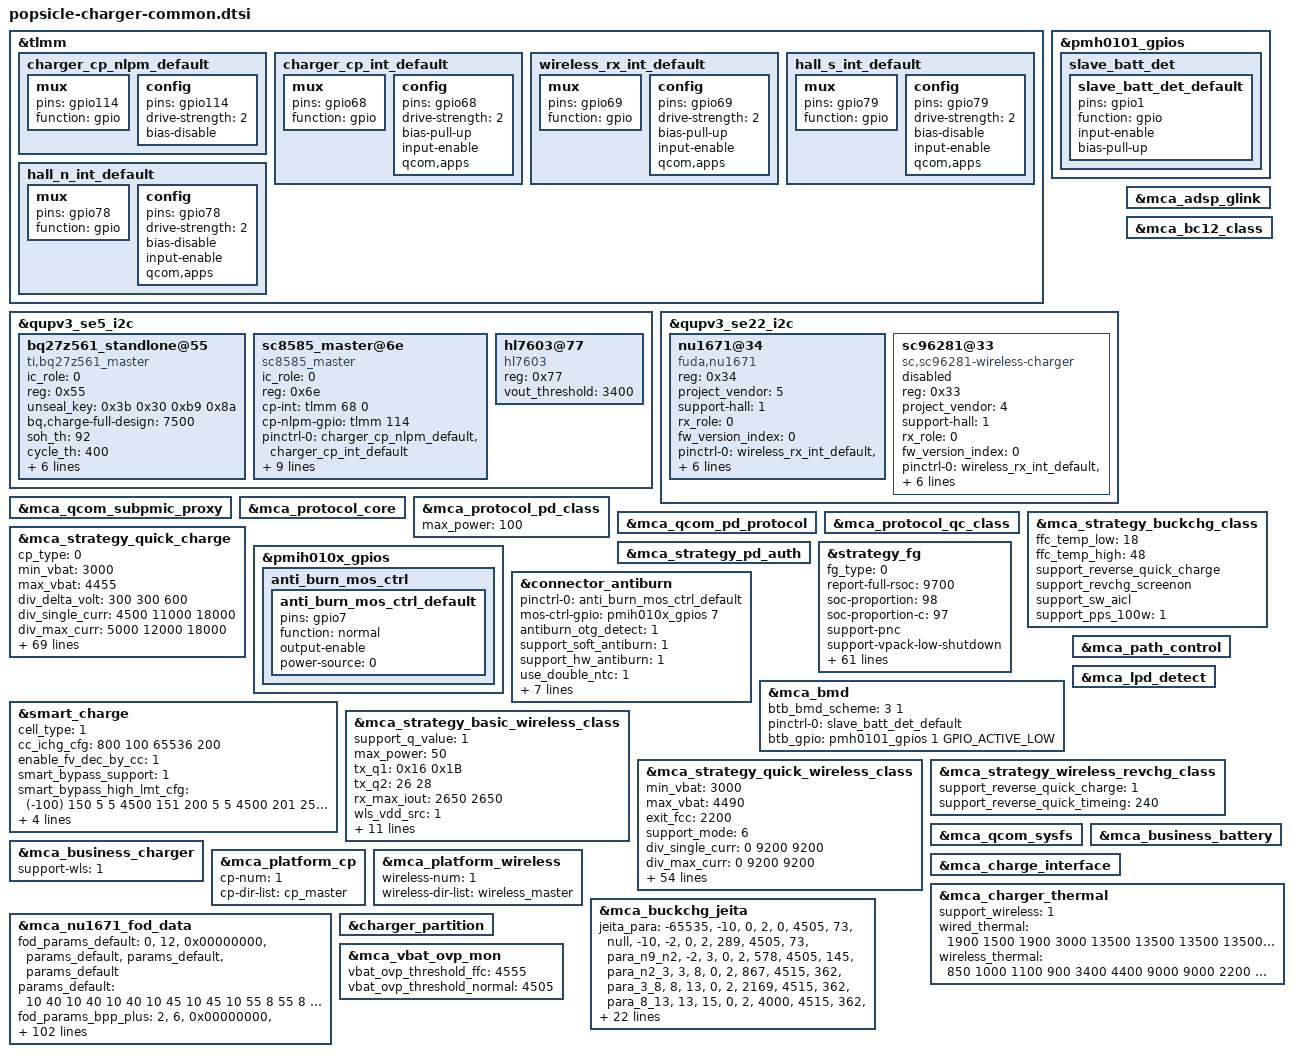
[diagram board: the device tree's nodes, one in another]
#include "mca.dtsi"

&tlmm {
	charger_cp_nlpm_default: charger_cp_nlpm_default {
		mux {
			pins = "gpio114";
			function = "gpio";
		};
		config {
			pins = "gpio114";
			drive-strength = <2>;   /* 2 mA */
			bias-disable;
		};
	};

	charger_cp_int_default: charger_cp_int_default {
		mux {
			pins = "gpio68";
			function = "gpio";
		};
		config {
			pins = "gpio68";
			drive-strength = <2>;   /* 2 mA */
			bias-pull-up;
			input-enable;
			qcom,apps;
		};
	};

	wireless_rx_int_default: wireless_rx_int_default {
		mux {
			pins = "gpio69";
			function = "gpio";
		};

		config {
			pins = "gpio69";
			drive-strength = <2>;
			bias-pull-up;
			input-enable;
			qcom,apps;
		};
	};

	hall_s_int_default: hall_s_int_default {
		mux {
			pins = "gpio79";
			function = "gpio";
		};

		config {
			pins = "gpio79";
			drive-strength = <2>;
			bias-disable;
			input-enable;
			qcom,apps;
		};
	};

	hall_n_int_default: hall_n_int_default {
		mux {
			pins = "gpio78";
			function = "gpio";
		};

		config {
			pins = "gpio78";
			drive-strength = <2>;
			bias-disable;
			input-enable;
			qcom,apps;
		};
	};

};

&pmh0101_gpios {
	slave_batt_det {
		slave_batt_det_default: slave_batt_det_default {
			pins = "gpio1";
			function = "gpio";
			input-enable;
			bias-pull-up;
		};
	};
};


&qupv3_se5_i2c {
	status = "ok";
	#address-cells = <1>;
	#size-cells = <0>;
	bq27z561_standlone@55 {
		compatible = "ti,bq27z561_master";
		ic_role = <0>;
		reg = <0x55>;
		unseal_key = /bits/ 8 <0x3b 0x30 0xb9 0x8a>;
		bq,charge-full-design = <7500>;
		soh_th = <92>;
		cycle_th = <400>;
		cycle_step = <50>;
		resistance-id = <100000>;
		support_batt_manager_4p0;
		base_termv = <2850>;
		delta_soh_compesation = <
			0 0
			50 0
			100 2
			150 4
			200 6
			250 8
			300 10
			350 12
			400 14
			450 16
			500 18
			550 19>;
		status = "ok";
	};

	sc8585_master@6e {
		compatible = "sc8585_master";
		status = "ok";
		ic_role = <0>;
		reg = <0x6e>;
		cp-int= <&tlmm 68 0>;
		cp-nlpm-gpio = <&tlmm 114 0x00>;
		pinctrl-names = "default";
		pinctrl-0 = <&charger_cp_nlpm_default>, <&charger_cp_int_default>;
		bat-ovp-threshold = <4775>;
		bat-ovp-alarm-threshold = <4650>;
		bus-ovp-threshold = <21000 12000 6000>;
		usb-ovp-threshold = <21000 14000 7500>;
		bus-ocp-threshold = <5000 5500 5000>;
		wpc-ovp-threshold = <21000>;
		out-ovp-threshold = <5000>;
		pmid2-uvp-threshold = <350 350 100>;
		pmid2-ovp-threshold = <600>;
	};

	hl7603@77 {
		compatible = "hl7603";
		reg = <0x77>;
		vout_threshold = <3400>;
	};
};

&qupv3_se22_i2c {
	status = "ok";
	#address-cells = <1>;
	#size-cells = <0>;

	nu1671@34 {
		compatible = "fuda,nu1671";
		reg = <0x34>;
		project_vendor = <5>;
		support-hall = <1>;
		rx_role = <0>;
		fw_version_index = <0>;
		pinctrl-names = "default";
		pinctrl-0 = <&wireless_rx_int_default>, <&hall_s_int_default>, <&hall_n_int_default>;
		rx-int = <&tlmm 69 0x00>;
		pwr-det-int = <&tlmm 57 0x00>;
		sleep-rx-gpio = <&tlmm 200 0x00>;
		hall-s-int = <&tlmm 79 0x00>;
		hall-n-int = <&tlmm 78 0x00>;
	};

	sc96281@33 {
		status = "disabled";
		compatible = "sc,sc96281-wireless-charger";
		reg = <0x33>;
		project_vendor = <4>;
		support-hall = <1>;
		rx_role = <0>;
		fw_version_index = <0>;
		pinctrl-names = "default";
		pinctrl-0 = <&wireless_rx_int_default>, <&hall_s_int_default>, <&hall_n_int_default>;
		rx-int = <&tlmm 69 0x00>;
		pwr-det-int = <&tlmm 57 0x00>;
		sleep-rx-gpio = <&tlmm 200 0x00>;
		hall-s-int = <&tlmm 79 0x00>;
		hall-n-int = <&tlmm 78 0x00>;
	};
};

&mca_adsp_glink {
	status = "ok";
};

&mca_bc12_class {
	status = "ok";
};

&mca_qcom_subpmic_proxy {
	status = "ok";
};

&mca_protocol_core {
	status = "ok";
};

&mca_protocol_pd_class {
	status = "ok";
	max_power = <100>;
};

&mca_qcom_pd_protocol {
	status = "ok";
};

&mca_protocol_qc_class {
	status = "ok";
};

&mca_strategy_buckchg_class {
	status = "ok";
	ffc_temp_low = <18>;
	ffc_temp_high = <48>;
	support_reverse_quick_charge;
	support_revchg_screenon;
	support_sw_aicl;
	support_pps_100w = <1>;
};

&mca_strategy_quick_charge {
	status = "ok";
	cp_type = <0>;
	min_vbat = <3000>;
	max_vbat = <4455>;
	div_delta_volt = <300 300 600>;
	div_single_curr = <4500 11000 18000>;
	div_max_curr = <5000 12000 18000>;
	non_mi_pps_max_curr = <4500 11000 18000>;
	support_mode = <6>;
	support_cp_vfc = <1>;
	real_curr_max = <17500>;
	curr_monitor_current = <17600>;
	curr_monitor_time_s = <120>;
	support_cancel_compensation;
	max_vbat_threshold = <4500>;
	en_buck_parallel_chg = <1>;
	buck_icl_fcc_curr = <1000 3000>;
	buck_en_th = <13000 2500>;
	buck_dis_th = <13000 3850>;

	/* volt_ratio, cur_gap, vbat_gap, vstep_ratio */
	vstep_para =
		"1", "300", "2000", "0", "2",
		"2", "300", "2000", "0", "4",
		"4", "300", "8400", "20", "20",
		"4", "300", "4400", "20", "10",
		"4", "300", "1400", "10", "5",
		"4", "300", "900", "10", "2",
		"1", "800", "2000", "0", "2",
		"2", "800", "2000", "0", "4",
		"4", "800", "8000", "0", "10",
		"4", "800", "6000", "0", "5",
		"4", "800", "4000", "0", "2";

	batt_para =
		"0", "atl", "batt_para_atl";
	/* temp_low, temp_high, low_hys, high_hys, max_curr, normal_para, ffc_para, normal_stage, ffc_stage */
	batt_para_atl =
		"-65535", "13", "0", "2", "0", "null", "null", "null", "null",
		"13", "15", "0", "1", "4338", "normal_para_13_15", "null", "null", "null",
		"15", "18", "0", "1", "7953", "normal_para_15_18", "null", "null", "null",
		"18", "23", "0", "1", "10845", "normal_para_18_23", "ffc_para_18_23", "null", "ffc_stage_18_23",
		"23", "25", "0", "1", "18000", "normal_para_23_25", "ffc_para_23_25", "null", "ffc_stage_23_25",
		"25", "35", "0", "0", "18000", "normal_para_25_35", "ffc_para_25_35", "null", "ffc_stage_25_35",
		"35", "43", "1", "0", "18000", "normal_para_35_43", "ffc_para_35_43", "null", "ffc_stage_35_43",
		"43", "48", "1", "0", "18000", "normal_para_43_48", "ffc_para_43_48", "null", "ffc_stage_43_48",
		"48", "65535", "2", "0", "0", "null", "null", "null", "null";

	/* volt, curr_max, curr_min */
	normal_para_13_15 =
		"3895", "4338", "2892",
		"4510", "2892", "800";

	normal_para_15_18 =
		"3995", "7953", "5784",
		"4145", "5784", "2892",
		"4510", "2892", "800";

	normal_para_18_23 =
		"3895", "10845", "7953",
		"3995", "7953", "5784",
		"4145", "5784", "2892",
		"4490", "2892", "800";
	ffc_para_18_23 =
		"3895", "10845", "7953",
		"3995", "7953", "5784",
		"4145", "5784", "2892",
		"4540", "2892", "940";
	ffc_stage_18_23 = <0 1 0 0 0 0 0 0>;

	normal_para_23_25 =
		"4015", "18000", "8676",
		"4395", "8676", "5784",
		"4490", "5784", "800";
	ffc_para_23_25 =
		"4015", "18000", "12400",
		"4105", "12400", "10845",
		"4295", "10845", "8676",
		"4395", "8676", "5784",
		"4540", "5784", "1736";
	ffc_stage_23_25 = <0 0 0 0 0 0 0 0 0 0>;

	normal_para_25_35 =
		"4015", "18000", "8676",
		"4490", "8676", "800";
	ffc_para_25_35 =
		"4015", "18000", "12400",
		"4105", "12400", "10845",
		"4495", "10845", "8676",
		"4540", "8676", "1736";
	ffc_stage_25_35 = <0 0 0 0 0 0 0 0>;

	normal_para_35_43 =
		"4015", "18000", "8676",
		"4470", "8676", "800";
	ffc_para_35_43 =
		"4015", "18000", "12400",
		"4105", "12400", "10845",
		"4495", "10845", "8676",
		"4540", "8676", "3109";
	ffc_stage_35_43 = <0 0 0 0 0 0 0 0>;

	normal_para_43_48 =
		"4015", "18000", "8676",
		"4470", "8676", "800";
	ffc_para_43_48 =
		"4015", "18000", "12400",
		"4105", "12400", "10845",
		"4495", "10845", "8676",
		"4540", "8676", "5712";
	ffc_stage_43_48 = <0 0 0 0 0 0 0 0>;
};

&mca_strategy_pd_auth {
	status = "ok";
};

&strategy_fg {
	status = "ok";
	fg_type = <0>;
	report-full-rsoc = <9700>;
	soc-proportion = <98>;
	soc-proportion-c = <97>;
	support-pnc;

	support-vpack-low-shutdown;
	vcutoff_shutdown_delay = <3030>;
	vcutoff_sw = <2930>;
	vcutoff_fw = <3030>;

	support-cc-vcutoff;
	/* temp_low, temp_high, low_temp_hys, high_temp_hys, vterm_para_name */
	cc_vcutoff_cfg =
		"-65535", "-6", "0", "2", "cc_para0",
		"-6", "0", "2", "2", "cc_para1",
		"0", "10", "2", "2", "cc_para2",
		"10", "60", "2", "0", "cc_para3",
		"60", "65535", "2", "0", "cc_para4";
	/* cycle_count, vterm_fw, vterm_shutdown_delay, vempty */
	cc_para0 =
		"400", "2650", "2600", "2500",
		"800", "2700", "2650", "2550",
		"1200", "2850", "2800", "2700",
		"65535", "2950", "2900", "2800";
	cc_para1 =
		"400", "2700", "2650", "2550",
		"800", "2850", "2800", "2700",
		"1200", "2950", "2900", "2800",
		"65535", "3050", "3000", "2900";
	cc_para2 =
		"400", "2850", "2850", "2750",
		"800", "2950", "2950", "2850",
		"1200", "3000", "3000", "2900",
		"65535", "3100", "3100", "3000";
	cc_para3 =
		"400", "3030", "3030", "2930",
		"800", "3130", "3130", "3030",
		"1200", "3200", "3200", "3100",
		"65535", "3260", "3260", "3160";
	cc_para4 =
		"65535", "3260", "3260", "3160";

	support-dod-vcutoff-v2;
	weight = <20 18 15>;
	/* temp_low, temp_high, low_temp_hys, high_temp_hys, vterm_para_name */
	dod_vcutoff_cfg =
		"-65535", "-6", "0", "2", "dod_para0",
		"-6", "0", "2", "2", "dod_para1",
		"0", "10", "2", "2", "dod_para2",
		"10", "60", "2", "0", "dod_para3",
		"60", "65535", "2", "0", "dod_para4";
	/* dod_count, vterm_fw, vterm_shutdown_delay, vempty */
	dod_para0 =
		"79", "2650", "2600", "2500",
		"159", "2700", "2650", "2550",
		"413", "2850", "2800", "2700",
		"1050", "2950", "2900", "2800",
		"65535", "3050", "3000", "2900";
	dod_para1 =
		"79", "2700", "2650", "2550",
		"159", "2850", "2800", "2700",
		"413", "2950", "2900", "2800",
		"1050", "3050", "3000", "2900",
		"65535", "3150", "3100", "3000";
	dod_para2 =
		"79", "2850", "2850", "2750",
		"159", "2950", "2950", "2850",
		"413", "3000", "3000", "2900",
		"1050", "3100", "3100", "3000",
		"65535", "3200", "3200", "3100";
	dod_para3 =
		"79", "3030", "3030", "2930",
		"159", "3130", "3130", "3030",
		"413", "3200", "3200", "3100",
		"1050", "3260", "3260", "3160",
		"65535", "3310", "3310", "3210";
	dod_para4 =
		"65535", "3310", "3310", "3210";

	adapt_power = <100>;
	model-name = "P2_7500mah_100w";
	charge-full-design = <7500>;
	capacity_comp = <450000>;
	support_dtpt = <1>;
	fg_hightemp_vterm = <4200>;
	support-lossless-rechg = <1>;
	lossless_rechg_cfg = <15 47 90>;
	support_normal_force_full;
	normal_force_full_hys = <116>;
	suppot_RSOC_0_smooth = <1>;
	smooth_temp_unit = <0 150>; //15℃
	smooth_curr_unit = <0 300000 600000 1000000 >;
	smooth_vol_offset = <0x80000000 0 100 200 300 >;
	dischg_smooth_low_temp_unit = <
		10 10 10 10
		20 10 10 10
		40 20 10 10
		80 40 30 20
		150 80 70 50 >;
	dischg_smooth_high_temp_unit = <
		10 10 10 10
		30 20 10 10
		60 40 20 10
		150 70 50 40
		200 150 100 70 >;
	support_extreme_cold = <2>;
	extreme_cold_temp_compemsation =
		"2147483647", "50", "90",
		"2147483647", "600", "80";
};

&pmih010x_gpios {
	anti_burn_mos_ctrl {
		anti_burn_mos_ctrl_default: anti_burn_mos_ctrl_default {
			pins = "gpio7";
			function = "normal";
			output-enable;
			//drive-strength = <2>;
			power-source = <0>;
		};
	};
};

&connector_antiburn {
	status = "ok";
	pinctrl-names = "default";
	pinctrl-0 = <&anti_burn_mos_ctrl_default>;
	mos-ctrl-gpio = <&pmih010x_gpios 7 0>;
	antiburn_otg_detect = <1>;
	support_soft_antiburn = <1>;
	support_hw_antiburn = <1>;
	use_double_ntc = <1>;
	monitor_interval = <1000>;
	thermal-zone-name = "conn_therm";
	thermal-zone-name2 = "conn_therm2";
	max_temp_increase_rate = <4>; /*ntc temperature increase speed per second.*/
	otg_boost_src = <1>; /* HBOOST */
	en_src = <0>; /* OTG_EN_BOOST */
	thermal-board-temp-name = "board_sensor_therm";
};

&mca_bmd {
	status = "ok";
	btb_bmd_scheme = <3 1>;
	pinctrl-names = "default";
	pinctrl-0 = <&slave_batt_det_default>;
	btb_gpio = <&pmh0101_gpios 1 GPIO_ACTIVE_LOW>;
};

&smart_charge {
	status = "ok";
	cell_type = <1>;
	// support_cc_ichg;
	/* cyclecount delta_ichg*/
	cc_ichg_cfg = <
		800 100
		65536 200>;
	enable_fv_dec_by_cc = <1>;
	smart_bypass_support = <1>;

	/* temp_low, temp_high, low_temp_hys, high_temp_hys, fcc */
	smart_bypass_high_lmt_cfg = <
		(-100) 150 5 5 4500
		151 200 5 5 4500
		201	250	5 5 4500
		251	300	5 5 3500
		301	370	5 5 2500
		371	800	5 5 1000>;
	smart_bypass_med_lmt_cfg = <
		(-100) 150 5 5 18000
		151	200	5 5 18000
		201	250	5 5 18000
		251	300	5 5 8000
		301	370	5 5 5000
		371	800	5 5 2000>;
	smart_bypass_low_lmt_cfg = <
		(-100) 150 5 5 18000
		151	200	5 5 18000
		201	250	5 5 18000
		251	300	5 5 9000
		301	370	5 5 5000
		371	800	5 5 3000>;
};

&mca_path_control {
	status = "ok";
};

&mca_lpd_detect {
	status = "ok";
};

&mca_strategy_basic_wireless_class {
	status = "ok";
	support_q_value = <1>;
	max_power = <50>;
	/* low_inductance_tx_50w, low_inductance_tx_80w */
	tx_q1 = /bits/ 8 <0x16 0x1B>;
	tx_q2 = <26 28>;
	rx_max_iout = <2650 2650>;
	wls_vdd_src = <1>;
	ffc_temp_low = <18>;
	ffc_temp_high = <48>;
	support-hall = <1>;

	camera-wa-affected-tx-uuid = <0x09058903 0x09058907 0x0E018207 0x09018B07>;
	camera-wa-target-freq = <128 128 128 128>;

	support-dynamic-cp = <1>;
	dynamic-cp-uuid = <0x09010a01>;
	dynamic-cp-min-tx-adapter = <14>;
	dynamic-cp-4to2-threshold = <4000>;
	dynamic-cp-2-1-max-fcc = <4000>;
};

&mca_strategy_quick_wireless_class {
	status = "ok";
	min_vbat = <3000>;
	max_vbat = <4490>;
	exit_fcc = <2200>;
	support_mode = <6>;
	div_single_curr = <0 9200 9200>;
	div_max_curr = <0 9200 9200>;
	rx-die-temp-thre = <64>;
	rx-high-die-temp-fcc = <7000>;
	support-hall = <1>;

	batt_para =
		"0", "atl", "batt_para_atl";
	/* temp_low, temp_high, low_hys, high_hys, max_curr, normal_para, ffc_para, normal_stage, ffc_stage */
	batt_para_atl =
		"-65535", "13", "0", "0", "0", "null", "null", "null", "null",
		"13", "15", "0", "1", "4338", "normal_para_13_15", "null", "null", "null",
		"15", "18", "0", "1", "7953", "normal_para_15_18", "null", "null", "null",
		"18", "23", "0", "1", "10845", "normal_para_18_23", "ffc_para_18_23", "null", "ffc_stage_18_23",
		"23", "25", "0", "1", "17600", "normal_para_23_25", "ffc_para_23_25", "null", "ffc_stage_23_25",
		"25", "35", "0", "0", "17600", "normal_para_25_35", "ffc_para_25_35", "null", "ffc_stage_25_35",
		"35", "43", "1", "0", "17600", "normal_para_35_43", "ffc_para_35_43", "null", "ffc_stage_35_43",
		"43", "48", "1", "0", "17600", "normal_para_43_48", "ffc_para_43_48", "null", "ffc_stage_43_48",
		"48", "65535", "0", "0", "0", "null", "null", "null", "null";

	/* volt, curr_max, curr_min */
	normal_para_13_15 =
		"3900", "4338", "2892",
		"4505", "2892", "1300";

	normal_para_15_18 =
		"4000", "7953", "5784",
		"4150", "5784", "2892",
		"4505", "2892", "1300";

	normal_para_18_23 =
		"3900", "10845", "7953",
		"4000", "7953", "5784",
		"4150", "5784", "2892",
		"4485", "2892", "1300";
	ffc_para_18_23 =
		"3900", "10845", "7953",
		"4000", "7953", "5784",
		"4150", "5784", "2892",
		"4485", "2892", "1300";
	ffc_stage_18_23 = <0 1 0 1 0 1 0 1 0 1>;

	normal_para_23_25 =
		"4020", "17600", "8676",
		"4400", "8676", "5784",
		"4485", "5784", "1300";
	ffc_para_23_25 =
		"4010", "17600", "12400",
		"4110", "12400", "10845",
		"4300", "10845", "8676",
		"4400", "8676", "5784",
		"4485", "5784", "1300";
	ffc_stage_23_25 = <0 1 0 1 0 1 0 1 0 1>;

	normal_para_25_35 =
		"4020", "17600", "8676",
		"4485", "8676", "1300";
	ffc_para_25_35 =
		"4020", "17600", "12400",
		"4110", "12400", "10845",
		"4485", "8676", "1300";
	ffc_stage_25_35 = <0 1 0 1 0 1 0 1 0 1>;

	normal_para_35_43 =
		"4020", "17600", "8676",
		"4465", "8676", "1300";
	ffc_para_35_43 =
		"4020", "17600", "12400",
		"4110", "12400", "10845",
		"4465", "8676", "1300";
	ffc_stage_35_43 = <0 1 0 1 0 1 0 1 0 1>;

	normal_para_43_48 =
		"4020", "17600", "8676",
		"4465", "8676", "1300";
	ffc_para_43_48 =
		"4020", "17600", "12400",
		"4110", "12400", "10845",
		"4465", "8676", "1300";
	ffc_stage_43_48 = <0 1 0 1 0 1 0 1 0 1>;

	vstep_para =
		"1", "2000", "2",
		"2", "2000", "4",
		"4", "4000", "25",
		"4", "3000", "25",
		"4", "2000", "6",
		"4", "1000", "3",
		"4", "500", "2",
		"4", "200", "1";
};

&mca_strategy_wireless_revchg_class {
	status = "ok";
	support_reverse_quick_charge = <1>;
	support_reverse_quick_timeing = <240>;  //sec
};

&mca_qcom_sysfs {
	status = "ok";
};

&mca_business_battery {
	status = "ok";
};

&mca_business_charger {
	support-wls = <1>;
	status = "ok";
};

&mca_platform_cp {
	status = "ok";
	cp-num = <1>;
	cp-dir-list = "cp_master";
};

&mca_platform_wireless {
	status = "ok";
	wireless-num = <1>;
	wireless-dir-list = "wireless_master";
};

&mca_charge_interface {
	status = "ok";
};

&mca_charger_thermal {
	status = "ok";
	support_wireless = <1>;
	/* 5v_in 9v_in 5v_ichg 9v_ichg div1_single div1_multi div2_single div2_multi div4_single div4_multi*/
	wired_thermal = <
		1900 1500 1900 3000 13500 13500 13500 13500 13500 13500 /* level 1 */
		1900 1500 1900 3000 11000 11000 11000 11000 11000 11000 /* level 2 */
		1900 1500 1900 3000 9000  9000  9000  9000  9000  9000  /* level 3 */
		1900 1450 1900 3000 8000  8000  8000  8000  8000  8000  /* level 4 */
		1900 1400 1900 3000 7000  7000  7000  7000  7000  7000  /* level 5 */
		1900 1350 1900 2800 6000  6000  6000  6000  6000  6000  /* level 6 */
		1900 1300 1900 2600 5000  5000  5000  5000  5000  5000  /* level 7 */
		1900 1150 1900 2310 4000  4000  4000  4000  4000  4000  /* level 8 */
		1700 1100 1700 2200 3500  3500  3500  3500  3500  3500  /* level 9 */
		1600 1000 1600 2000 3000  3000  3000  3000  3000  3000  /* level 10 */
		1400 900  1500 2000 2500  2500  2500  2500  2500  2500  /* level 11 */
		1200 850  1500 2000 2000  2000  2000  2000  2000  2000  /* level 12 */
		1100 750  1500 1500 1500  1500  1500  1500  1500  1500  /* level 13 */
		1100 650  1000 1000 1000  1000  1000  1000  1000  1000  /* level 14 */
		1100 600  500  500  500   500   500   500   500   500   /* level 15 */
	>;
	/* bpp_in bpp_qc2 bpp_qc3 epp_in cp_20w cp_30w cp_50w cp_80w voice_box magnet_30w*/
	wireless_thermal = <
		850 1000 1100 900 3400 4400 9000 9000 2200 4400 /* level 1 */
		850 1000 1100 750 3200 4200 8000 8000 2200 4200 /* level 2 */
		850 1000 1100 650 2200 3400 7000 7000 1000 3400 /* level 3 */
		700 1000 1100 650 1800 2800 6000 6000 1000 2800 /* level 4 */
		700 1000  700 650 1500 2600 5000 5000  800 2600 /* level 5 */
		500 1000  700 650 1300 2200 4000 4000  800 2200 /* level 6 */
		500  700  600 400 1100 2200 3500 3500  700 2200 /* level 7 */
		500  700  600 400 1000 1800 3000 3000  700 1800 /* level 8 */
		500  500  500 300  800 1100 2500 2500  600 1500 /* level 9 */
		400  500  500 300  700 1000 2000 2000  600 1400 /* level 10 */
		400  500  500 250  600  800 1500 1500  500 1300 /* level 11 */
		400  500  500 250  500  700 1000 1000  500  900 /* level 12 */
		300  500  500 250  500  600  800  800  400  600 /* level 13 */
		300  400  400 200  400  500  500  500  400  500 /* level 14 */
		300  300  300 150  300  400  400  400  300  400 /* level 15 */
	>;
};

&mca_buckchg_jeita {
	status = "ok";
	/* temp_low, temp_high, low_temp_hys, high_temp_hys, max_current, vterm, iterm volt_para_name */
	jeita_para =
		"-65535", "-10", "0", "2", "0", "4505", "73", "null",
		"-10", "-2", "0", "2", "289", "4505", "73", "para_n9_n2",
		"-2", "3", "0", "2", "578", "4505", "145", "para_n2_3",
		"3", "8", "0", "2", "867", "4515", "362", "para_3_8",
		"8", "13", "0", "2", "2169", "4515", "362", "para_8_13",
		"13", "15", "0", "2", "4000", "4515", "362", "para_13_15",
		"15", "18", "0", "1", "4000", "4515", "362", "para_15_18",
		"18", "23", "0", "1", "4000", "4495", "362", "para_18_23",
		"23", "35", "0", "0", "4000", "4495", "362", "null",
		"35", "43", "1", "0", "4000", "4475", "362", "null",
		"43", "48", "1", "0", "4000", "4475", "362", "null",
		"48", "55", "2", "0", "3615", "4060", "362", "null",
		"55", "65535", "2", "2", "0", "4060", "362", "null";
	para_n9_n2 =
		"4000", "289",
		"4505", "144";
	para_n2_3 =
		"4000", "578",
		"4505", "361";
	para_3_8 =
		"4000", "867",
		"4200", "723",
		"4515", "578";
	para_8_13 =
		"3900", "2169",
		"4515", "1446";
	para_13_15 =
		"3900", "4000",
		"4515", "2892";
	para_15_18 =
		"4150", "4000",
		"4515", "2892";
	para_18_23 =
		"4150", "4000",
		"4495", "2314";
	jeita_para_ffc =
		"18", "23", "0", "1", "4000", "4545", "940", "para_ffc_18_23",
		"23", "25", "0", "1", "4000", "4545", "1736", "null",
		"25", "35", "0", "0", "4000", "4545", "1736", "null",
		"35", "43", "1", "0", "4000", "4545", "3109", "null",
		"43", "48", "1", "0", "4000", "4545", "5712", "null",
		"48", "55", "2", "0", "3615", "4060", "362", "null",
		"55", "65535", "2", "2", "0", "4060", "362", "null";
	para_ffc_18_23 =
		"4150", "4000",
		"4545", "2314";
};

&mca_nu1671_fod_data {
	/* type, length, uuid, params_no_mag, params_mag_thin, params_mag_thick */
	fod_params_default =
		"0", "12", "0x00000000", "params_default", "params_default", "params_default";
	params_default = /bits/ 8 <
		10  40
		10  40
		10  40
		10  45
		10  45
		10  55
		8   55
		8   47
		8   47
		8   47
		8   47
		8   47
	>;

	/* type, length, uuid, params_no_mag, params_mag_thin, params_mag_thick */
	fod_params_bpp_plus =
		"2", "6",  "0x00000000", "params_bpp_plus", "params_bpp_plus", "params_bpp_plus";
	params_bpp_plus = /bits/ 8 <
		10  20
		10  20
		8   20
		8   20
		8   20
		8   20
		8   20
	>;

	fod_params_2_1 =
		"1", "20", "0x09010A01", "params_m2_50W_2_1", "params_m2_50W_2_1_mag", "params_m2_50W_2_1_mag_thick",
		"1", "20", "0x09010305", "params_n1_80W_2_1", "params_n1_80W_2_1_mag", "params_n1_80W_2_1_mag_thick";
	/* gain, offset */
	params_m2_50W_2_1 = /bits/ 8 <
		0 45
		0 32
		0 30
		0 30
		0 21
		0 25
		0 25
		1 23
		1 22
		1 22
		1 23
		1 23
		2 24
		2 31
		2 33
		2 33
		2 33
		2 36
		2 36
		2 38
	>;
	params_m2_50W_2_1_mag = /bits/ 8 <
		0 50
		0 48
		0 48
		0 32
		0 26
		0 27
		0 24
		1 25
		1 26
		1 26
		1 26
		1 28
		2 30
		2 31
		2 33
		2 33
		2 33
		2 36
		2 36
		2 38
	>;
	params_m2_50W_2_1_mag_thick = /bits/ 8 <
		0 45
		0 44
		0 44
		0 32
		0 23
		0 24
		0 22
		1 21
		1 23
		1 23
		1 24
		1 26
		2 26
		2 31
		2 33
		2 33
		2 33
		2 36
		2 36
		2 38
	>;

	params_n1_80W_2_1 = /bits/ 8 <
		0 30
		0 25
		0 20
		0 15
		0 13
		0 17
		0 17
		1 20
		1 24
		1 26
		1 29
		1 35
		2 26
		2 26
		2 28
		2 28
		2 28
		2 31
		2 31
		2 33
	>;
	params_n1_80W_2_1_mag = /bits/ 8 <
		0 30
		0 25
		0 20
		0 12
		0 13
		0 17
		0 22
		1 25
		1 19
		1 24
		1 30
		1 30
		2 26
		2 26
		2 28
		2 28
		2 28
		2 31
		2 31
		2 33
	>;
	params_n1_80W_2_1_mag_thick = /bits/ 8 <
		0 30
		0 25
		0 10
		0 10
		0 8
		0 7
		0 12
		1 10
		1 19
		1 21
		1 20
		1 30
		2 26
		2 26
		2 28
		2 28
		2 28
		2 31
		2 31
		2 33
	>;

	/* type, length, uuid, params_no_mag, params_mag_thin, params_mag_thick */
	fod_params =
		"1", "20", "0x09010901", "params_l2_50W", "params_l2_50W_mag", "params_l2_50W_mag_thick",
		"0", "12", "0x09010A01", "params_m2_50W", "params_m2_50W_mag", "params_m2_50W_mag_thick",
		"1", "20", "0x09010904", "params_k1_80W", "params_k1_80W_mag", "params_k1_80W_mag_thick",
		"1", "20", "0x0901090C", "params_k8_100W", "params_k8_100W_mag", "params_k8_100W_mag_thick",
		"1", "20", "0x0E018207", "params_magnet_black_car_30W_mag", "params_magnet_black_car_30W_mag", "params_magnet_black_car_30W_mag_thick",
		"1", "20", "0x09010907", "params_redmi_disc_30W", "params_redmi_disc_30W_mag", "params_redmi_disc_30W_mag_thick",
		"0", "12", "0x09010305", "params_n1_80W", "params_n1_80W_mag", "params_n1_80W_mag_thick",
		"1", "20", "0x09010A07", "params_double_coil_30W", "params_double_coil_30W_mag", "params_double_coil_30W_mag_thick",
		"1", "20", "0x09018B07", "params_magnet_30W_mag", "params_magnet_30W_mag", "params_magnet_30W_mag_thick",
		"1", "20", "0x09058907", "params_magnet_2in1_30W_mag", "params_magnet_2in1_30W_mag", "params_magnet_2in1_30W_mag_thick";

	params_l2_50W = /bits/ 8 <
		0 30
		0 20
		0 20
		0 20
		0 23
		0 27
		0 27
		1 25
		1 29
		1 29
		1 31
		1 35
		2 31
		2 31
		2 33
		2 33
		2 33
		2 36
		2 36
		2 38
	>;
	params_l2_50W_mag = /bits/ 8 <
		0 30
		0 20
		0 20
		0 20
		0 23
		0 27
		0 27
		1 25
		1 29
		1 29
		1 31
		1 35
		2 31
		2 31
		2 33
		2 33
		2 33
		2 36
		2 36
		2 38
	>;
	params_l2_50W_mag_thick = /bits/ 8 <
		0 30
		0 20
		0 20
		0 20
		0 23
		0 25
		0 22
		1 25
		1 23
		1 21
		1 23
		1 30
		2 20
		2 27
		2 37
		2 23
		2 28
		2 36
		2 36
		2 38
	>;

	params_m2_50W = /bits/ 8 <
		10 40
		10 30
		10 30
		8  37
		7  36
		7  43
		7  40
		7  37
		7  37
		7  37
		7  37
		7  37
	>;
	params_m2_50W_mag = /bits/ 8 <
		10 68
		10 60
		10 65
		10 65
		10 45
		10 43
		7  45
		7  57
		7  57
		7  57
		7  37
		7  37
	>;
	params_m2_50W_mag_thick = /bits/ 8 <
		10 55
		10 40
		10 40
		10 45
		10 33
		10 27
		7  37
		7  37
		7  37
		7  37
		7  37
		7  37
	>;

	params_magnet_30W_mag = /bits/ 8 <
		0 20
		0 18
		0 18
		0 16
		0 23
		0 22
		0 26
		1 28
		1 31
		1 38
		1 51
		1 50
		2 51
		2 51
		2 51
		2 51
		2 51
		2 51
		2 51
		2 51
	>;
	params_magnet_30W_mag_thick = /bits/ 8 <
		0 20
		0 5
		0 13
		0 13
		0 17
		0 18
		0 22
		1 23
		1 27
		1 32
		1 40
		1 42
		2 47
		2 47
		2 47
		2 47
		2 47
		2 47
		2 47
		2 47
	>;

	params_magnet_2in1_30W_mag = /bits/ 8 <
		0 55
		0 48
		0 48
		0 41
		0 40
		0 32
		0 33
		1 35
		1 42
		1 49
		1 58
		1 65
		2 68
		2 75
		2 75
		2 75
		2 75
		2 75
		2 75
		2 75
	>;
	params_magnet_2in1_30W_mag_thick = /bits/ 8 <
		0 55
		0 48
		0 48
		0 41
		0 40
		0 35
		0 33
		1 35
		1 43
		1 49
		1 56
		1 62
		2 62
		2 75
		2 75
		2 75
		2 75
		2 75
		2 75
		2 75
	>;

	params_redmi_disc_30W = /bits/ 8 <
		0 30
		0 20
		0 20
		0 14
		0 23
		0 24
		0 25
		1 25
		1 29
		1 31
		1 37
		1 35
		2 31
		2 31
		2 33
		2 33
		2 33
		2 36
		2 36
		2 38
	>;
	params_redmi_disc_30W_mag = /bits/ 8 <
		0 35
		0 20
		0 20
		0 13
		0 18
		0 19
		0 19
		1 25
		1 24
		1 29
		1 35
		1 35
		2 31
		2 31
		2 33
		2 33
		2 33
		2 36
		2 36
		2 38
	>;
	params_redmi_disc_30W_mag_thick = /bits/ 8 <
		0 28
		0 20
		0 15
		0 12
		0 15
		0 17
		0 20
		1 17
		1 25
		1 25
		1 26
		1 30
		2 26
		2 51
		2 53
		2 53
		2 53
		2 56
		2 56
		2 58
	>;

	params_k8_100W = /bits/ 8 <
		0 40
		0 28
		0 28
		0 30
		0 26
		0 30
		0 33
		1 33
		1 37
		1 42
		1 48
		1 53
		2 52
		2 51
		2 61
		2 68
		2 75
		2 131
		2 131
		2 133
	>;
	params_k8_100W_mag = /bits/ 8 <
		0 35
		0 23
		0 23
		0 23
		0 23
		0 29
		0 29
		1 30
		1 34
		1 39
		1 43
		1 50
		2 49
		2 51
		2 55
		2 63
		2 69
		2 124
		2 129
		2 131
	>;
	params_k8_100W_mag_thick = /bits/ 8 <
		0 37
		0 23
		0 23
		0 23
		0 21
		0 24
		0 25
		1 25
		1 29
		1 33
		1 35
		1 40
		2 39
		2 41
		2 45
		2 48
		2 52
		2 105
		2 108
		2 110
	>;

	params_k1_80W = /bits/ 8 <
		0 57
		0 58
		0 58
		0 60
		0 48
		0 48
		0 48
		1 60
		1 62
		1 66
		1 72
		1 76
		2 84
		2 80
		2 89
		2 94
		2 102
		2 100
		2 114
		2 116
	>;
	params_k1_80W_mag = /bits/ 8 <
		0 77
		0 55
		0 53
		0 56
		0 55
		0 55
		0 60
		1 60
		1 63
		1 67
		1 77
		1 80
		2 80
		2 84
		2 90
		2 87
		2 92
		2 104
		2 110
		2 114
	>;
	params_k1_80W_mag_thick = /bits/ 8 <
		0 62
		0 49
		0 50
		0 50
		0 50
		0 53
		0 57
		1 59
		1 61
		1 61
		1 70
		1 75
		2 70
		2 74
		2 79
		2 85
		2 90
		2 98
		2 114
		2 116
	>;

	params_n1_80W = /bits/ 8 <
		10 10
		10 0
		8  0
		0  253
		0  254
		0  0
		0  3
		0  8
		0  10
		0  15
		0  5
		0  5
	>;
	params_n1_80W_mag = /bits/ 8 <
		10 0
		10 0
		8  0
		0  13
		0  246
		0  246
		0  241
		0  243
		0  254
		0  254
		0  5
		0  5
	>;
	params_n1_80W_mag_thick = /bits/ 8 <
		10 0
		10 0
		8  0
		0  239
		0  241
		0  241
		0  241
		0  236
		0  246
		0  254
		0  5
		0  5
	>;

	params_double_coil_30W = /bits/ 8 <
		0 40
		0 31
		0 38
		0 25
		0 26
		0 30
		0 34
		1 40
		1 44
		1 49
		1 55
		1 60
		2 62
		2 62
		2 64
		2 64
		2 64
		2 67
		2 67
		2 69
	>;
	params_double_coil_30W_mag = /bits/ 8 <
		0 44
		0 31
		0 35
		0 27
		0 26
		0 28
		0 37
		1 39
		1 44
		1 52
		1 57
		1 59
		2 62
		2 62
		2 62
		2 62
		2 62
		2 62
		2 62
		2 62
	>;
	params_double_coil_30W_mag_thick = /bits/ 8 <
		0 30
		0 19
		0 20
		0 13
		0 11
		0 11
		0 17
		1 20
		1 29
		1 29
		1 32
		1 42
		2 40
		2 40
		2 40
		2 40
		2 40
		2 42
		2 42
		2 45
	>;

	params_magnet_black_car_30W_mag = /bits/ 8 <
		0 25
		0 25
		0 25
		0 25
		0 28
		0 21
		0 12
		1 12
		1 13
		1 20
		1 26
		1 32
		2 25
		2 51
		2 53
		2 53
		2 79
		2 90
		2 95
		2 97
	>;
	params_magnet_black_car_30W_mag_thick = /bits/ 8 <
		0 25
		0 25
		0 25
		0 25
		0 28
		0 21
		0 10
		1 9
		1 11
		1 16
		1 18
		1 23
		2 19
		2 51
		2 53
		2 53
		2 79
		2 90
		2 95
		2 97
	>;
};

&charger_partition {
	status = "ok";
};

&mca_vbat_ovp_mon {
	status = "ok";
	vbat_ovp_threshold_ffc = <4555>;
	vbat_ovp_threshold_normal = <4505>;
};
